# RZT2H register map
Vendor: Renesas Electronics Corporation; Series: RZT; File version: 1.00.00
CPU: other r0p0, little endian, MPU, no FPU, VTOR, 4 interrupt priority bits, 624 interrupts
Registers are 32-bit, read-write, reset 0x0 unless marked. A register's access mark holds for its fields unless they carry their own. Offsets are from the block's base; [hi:lo] are bit positions; {n}, {i} and the like mark numbered series.

## MPU_AC — Master MPU Access Control
Base 0x81240000
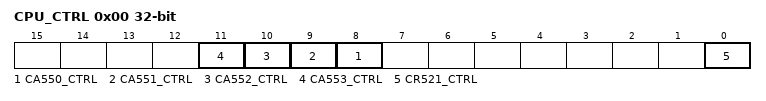
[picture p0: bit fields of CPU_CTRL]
0x00 CPU_CTRL — CPU Access Permission Control Register
  [all] fields
    0=Access prohibited; 1=Access permitted
  [n-542] CA{n}_CTRL (n=550..553)
  [0] CR521_CTRL

## CLMA0 — Clock Monitor Circuit 0
Base 0x81288000
Same registers: CLMA1 0x81288020, CLMA2 0x81288040, CLMA3 0x81288060, CLMA4 0x81288080, CLMA5 0x812880A0, CLMA6 0x812880C0
0x00 CTL0 8-bit — CLMA Control Register 0
  [0] CLME — Clock Monitor m Enable (m = 0 to 6)
    0=Disables CLMAm operation; 1=Enables CLMAm operation
0x08 CMPL 16-bit reset 0x1 — CLMA Compare Register L
  [11:0] CMPL — Clock Monitor m Compare L (m = 0 to 6)
0x0C CMPH 16-bit reset 0x3FF — CLMA Compare Register H
  [11:0] CMPH — Clock Monitor m Compare H (m = 0 to 6)
0x10 PCMD 8-bit wo — CLMA Command Register
0x14 PROTSR 8-bit ro — CLMA Protection Status Register
  [0] PRERR — CLMAm Error (m = 0 to 6)
    0=No protection error occurred; 1=A protection error occurred

## ADXC0 — Address Expander Control 0
Base 0x81290100
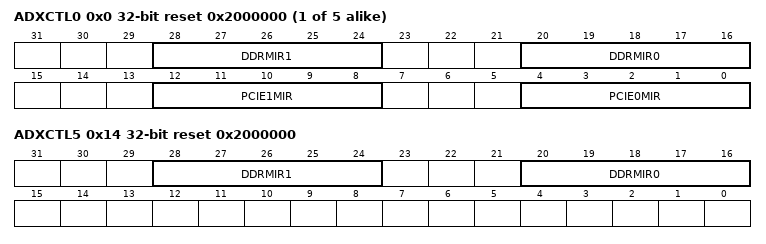
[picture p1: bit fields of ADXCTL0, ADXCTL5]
{0x0+4i} ADXCTL{i} (i=0..4) reset 0x2000000 — Address Expander Control Register {i}
  [28:24] DDRMIR1 — DDR Mirror Address 1
  [20:16] DDRMIR0 — DDR Mirror Address 0
  [12:8] PCIE1MIR — PCIE1 Mirror Address
  [4:0] PCIE0MIR — PCIE0 Mirror Address
0x14 ADXCTL5 reset 0x2000000 — Address Expander Control Register 5
  [28:24] DDRMIR1 — DDR Mirror Address 1
  [20:16] DDRMIR0 — DDR Mirror Address 0

## SSC — Slave Stop Control
Base 0x81290200
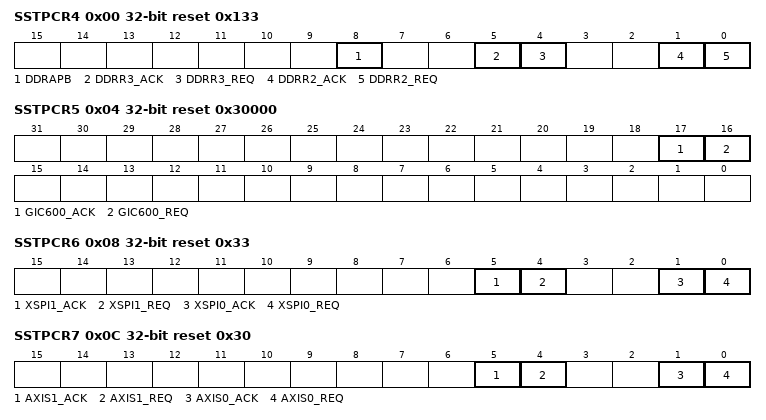
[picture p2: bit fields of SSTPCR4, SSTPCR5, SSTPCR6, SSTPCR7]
0x00 SSTPCR4 reset 0x133 — Slave Stop Control Register 4
  [8] DDRAPB
    0=Normal operation; 1=Stop
  [5] DDRR3_ACK ro
    0=Normal operation; 1=Bus Stop Acknowledge
  [4] DDRR3_REQ
    0=Normal operation; 1=Bus Stop Request
  [1] DDRR2_ACK ro
    0=Normal operation; 1=Bus Stop Acknowledge
  [0] DDRR2_REQ
    0=Normal operation; 1=Bus Stop Request
0x04 SSTPCR5 reset 0x30000 — Slave Stop Control Register 5
  [17] GIC600_ACK ro
    0=Normal operation; 1=Bus Stop Acknowledge
  [16] GIC600_REQ
    0=Normal operation; 1=Bus Stop Request
0x08 SSTPCR6 reset 0x33 — Slave Stop Control Register 6
  [5] XSPI1_ACK ro
    0=Normal operation; 1=Bus Stop Acknowledge
  [4] XSPI1_REQ
    0=Normal operation; 1=Bus Stop Request
  [1] XSPI0_ACK ro
    0=Normal operation; 1=Bus Stop Acknowledge
  [0] XSPI0_REQ
    0=Normal operation; 1=Bus Stop Request
0x0C SSTPCR7 reset 0x30 — Slave Stop Control Register 7
  [5] AXIS1_ACK ro
    0=Normal operation; 1=Bus Stop Acknowledge
  [4] AXIS1_REQ
    0=Normal operation; 1=Bus Stop Request
  [1] AXIS0_ACK ro
    0=Normal operation; 1=Bus Stop Acknowledge
  [0] AXIS0_REQ
    0=Normal operation; 1=Bus Stop Request
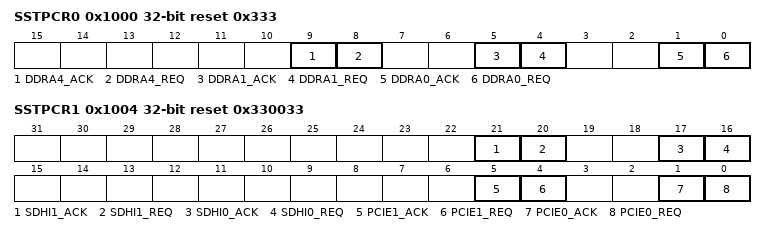
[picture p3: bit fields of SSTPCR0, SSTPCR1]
0x1000 SSTPCR0 reset 0x333 — Slave Stop Control Register 0
  [9] DDRA4_ACK ro
    0=Normal operation; 1=Bus Stop Acknowledge
  [8] DDRA4_REQ
    0=Normal operation; 1=Bus Stop Request
  [5] DDRA1_ACK ro
    0=Normal operation; 1=Bus Stop Acknowledge
  [4] DDRA1_REQ
    0=Normal operation; 1=Bus Stop Request
  [1] DDRA0_ACK ro — DDRSS A0 I/F Bus Stop Acknowledge
    0=Normal operation; 1=Bus Stop Acknowledge
  [0] DDRA0_REQ
    0=Normal operation; 1=Bus Stop Request
0x1004 SSTPCR1 reset 0x330033 — Slave Stop Control Register 1
  [21] SDHI1_ACK ro — SDHI1 I/F Bus Stop Acknowledge
    0=Normal operation; 1=Bus Stop Acknowledge
  [20] SDHI1_REQ
    0=Normal operation; 1=Bus Stop Request
  [17] SDHI0_ACK ro
    0=Normal operation; 1=Bus Stop Acknowledge
  [16] SDHI0_REQ
    0=Normal operation; 1=Bus Stop Request
  [5] PCIE1_ACK ro
    0=Normal operation; 1=Bus Stop Acknowledge
  [4] PCIE1_REQ
    0=Normal operation; 1=Bus Stop Request
  [1] PCIE0_ACK ro
    0=Normal operation; 1=Bus Stop Acknowledge
  [0] PCIE0_REQ
    0=Normal operation; 1=Bus Stop Request
